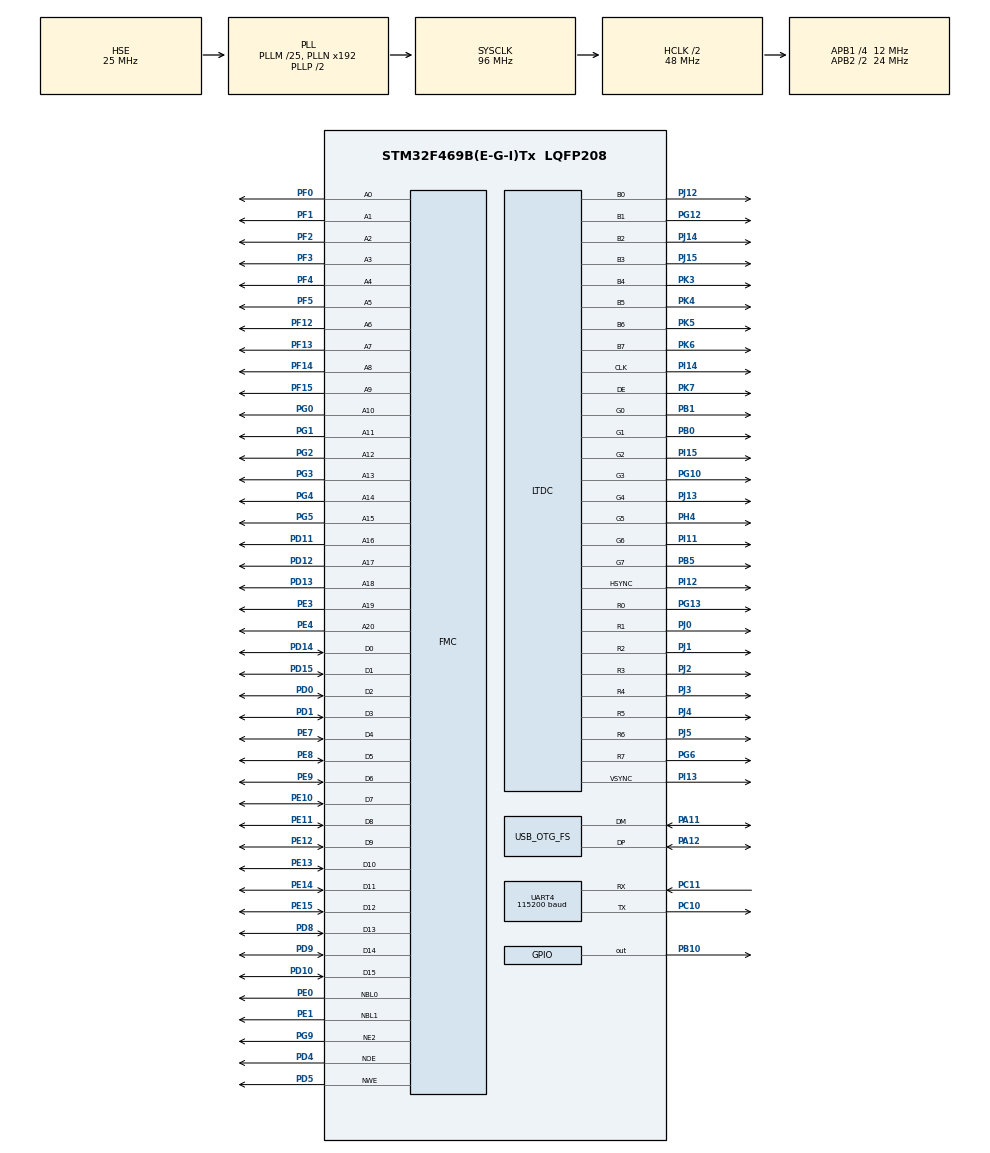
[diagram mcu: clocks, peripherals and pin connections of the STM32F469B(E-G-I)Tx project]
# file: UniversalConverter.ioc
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FMC.AddressSetupTime1=10
FMC.BusTurnAroundDuration1=2
FMC.DataSetupTime1=10
FMC.WriteFifo1=FMC_WRITE_FIFO_DISABLE
FMC.WriteFifo2=FMC_WRITE_FIFO_DISABLE
FMC.WriteFifo3=FMC_WRITE_FIFO_DISABLE
FMC.WriteFifo4=FMC_WRITE_FIFO_DISABLE
LTDC.ActiveW=800
LTDC.Blue=50
LTDC.Green=120
LTDC.HBP=40
LTDC.HFP=40
LTDC.HSync=48
LTDC.Red=255
LTDC.VBP=31
LTDC.VFP=13
LTDC.VSync=1
Mcu.Family=STM32F4
Mcu.Name=STM32F469B(E-G-I)Tx
Mcu.Package=LQFP208
NVIC.LTDC_IRQn=true\:0\:0\:false\:false\:true\:true\:true
NVIC.OTG_FS_IRQn=true\:0\:0\:false\:false\:true\:false\:true
NVIC.PriorityGroup=NVIC_PRIORITYGROUP_4
NVIC.UART4_IRQn=true\:0\:0\:false\:false\:true\:true\:true
PA11.Mode=Device_Only
PA11.Signal=USB_OTG_FS_DM
PA12.Mode=Device_Only
PA12.Signal=USB_OTG_FS_DP
PB0.GPIO_Mode=GPIO_MODE_AF_PP
PB0.GPIO_PuPd=GPIO_NOPULL
PB0.GPIO_Speed=GPIO_SPEED_FREQ_VERY_HIGH
PB0.Mode=RGB888
PB0.Signal=LTDC_G1
PB1.GPIO_Mode=GPIO_MODE_AF_PP
PB1.GPIO_PuPd=GPIO_NOPULL
PB1.GPIO_Speed=GPIO_SPEED_FREQ_VERY_HIGH
PB1.Mode=RGB888
PB1.Signal=LTDC_G0
PB10.GPIO_PuPd=GPIO_PULLUP
PB10.PinState=GPIO_PIN_SET
PB10.Signal=GPIO_Output
PB5.GPIO_Mode=GPIO_MODE_AF_PP
PB5.GPIO_PuPd=GPIO_NOPULL
PB5.GPIO_Speed=GPIO_SPEED_FREQ_VERY_HIGH
PB5.Mode=RGB888
PB5.Signal=LTDC_G7
PC10.Mode=Asynchronous
PC10.Signal=UART4_TX
PC11.Mode=Asynchronous
PC11.Signal=UART4_RX
PC14/OSC32_IN.Mode=LSE-External-Oscillator
PC14/OSC32_IN.Signal=RCC_OSC32_IN
PC15/OSC32_OUT.Mode=LSE-External-Oscillator
PC15/OSC32_OUT.Signal=RCC_OSC32_OUT
PD0.GPIO_Mode=GPIO_MODE_AF_PP
PD0.GPIO_PuPd=GPIO_PULLUP
PD0.Signal=FMC_D2_DA2
PD1.GPIO_PuPd=GPIO_PULLUP
PD1.Signal=FMC_D3_DA3
PD10.GPIO_PuPd=GPIO_PULLUP
PD10.Signal=FMC_D15_DA15
PD11.GPIO_PuPd=GPIO_PULLUP
PD11.Signal=FMC_A16_CLE
PD12.GPIO_PuPd=GPIO_PULLUP
PD12.Signal=FMC_A17_ALE
PD13.GPIO_PuPd=GPIO_PULLUP
PD13.Signal=FMC_A18
PD14.GPIO_PuPd=GPIO_PULLUP
PD14.Signal=FMC_D0_DA0
PD15.GPIO_PuPd=GPIO_PULLUP
PD15.Signal=FMC_D1_DA1
PD4.GPIO_PuPd=GPIO_PULLUP
PD4.Signal=FMC_NOE
PD5.GPIO_PuPd=GPIO_PULLUP
PD5.Signal=FMC_NWE
PD8.GPIO_PuPd=GPIO_PULLUP
PD8.Signal=FMC_D13_DA13
PD9.GPIO_PuPd=GPIO_PULLUP
PD9.Signal=FMC_D14_DA14
PE0.GPIO_PuPd=GPIO_PULLUP
PE0.Signal=FMC_NBL0
PE1.GPIO_PuPd=GPIO_PULLUP
PE1.Signal=FMC_NBL1
PE10.GPIO_PuPd=GPIO_PULLUP
PE10.Signal=FMC_D7_DA7
PE11.GPIO_PuPd=GPIO_PULLUP
PE11.Signal=FMC_D8_DA8
PE12.GPIO_PuPd=GPIO_PULLUP
PE12.Signal=FMC_D9_DA9
PE13.GPIO_PuPd=GPIO_PULLUP
PE13.Signal=FMC_D10_DA10
PE14.GPIO_PuPd=GPIO_PULLUP
PE14.Signal=FMC_D11_DA11
PE15.GPIO_PuPd=GPIO_PULLUP
PE15.Signal=FMC_D12_DA12
PE3.GPIO_PuPd=GPIO_PULLUP
PE3.Signal=FMC_A19
PE4.GPIO_PuPd=GPIO_PULLUP
PE4.Signal=FMC_A20
PE7.GPIO_PuPd=GPIO_PULLUP
PE7.Signal=FMC_D4_DA4
PE8.GPIO_PuPd=GPIO_PULLUP
PE8.Signal=FMC_D5_DA5
PE9.GPIO_PuPd=GPIO_PULLUP
PE9.Signal=FMC_D6_DA6
PF0.GPIO_PuPd=GPIO_PULLUP
PF0.Signal=FMC_A0
PF1.GPIO_PuPd=GPIO_PULLUP
PF1.Signal=FMC_A1
PF12.GPIO_PuPd=GPIO_PULLUP
PF12.Signal=FMC_A6
PF13.GPIO_PuPd=GPIO_PULLUP
PF13.Signal=FMC_A7
PF14.GPIO_PuPd=GPIO_PULLUP
PF14.Signal=FMC_A8
PF15.GPIO_PuPd=GPIO_PULLUP
PF15.Signal=FMC_A9
PF2.GPIO_PuPd=GPIO_PULLUP
PF2.Signal=FMC_A2
PF3.GPIO_PuPd=GPIO_PULLUP
PF3.Signal=FMC_A3
PF4.GPIO_PuPd=GPIO_PULLUP
PF4.Signal=FMC_A4
PF5.GPIO_PuPd=GPIO_PULLUP
PF5.Signal=FMC_A5
PG0.GPIO_PuPd=GPIO_PULLUP
PG0.Signal=FMC_A10
PG1.GPIO_PuPd=GPIO_PULLUP
PG1.Signal=FMC_A11
PG10.GPIO_Mode=GPIO_MODE_AF_PP
PG10.GPIO_PuPd=GPIO_NOPULL
PG10.GPIO_Speed=GPIO_SPEED_FREQ_VERY_HIGH
PG10.Mode=RGB888
PG10.Signal=LTDC_G3
PG12.GPIO_Mode=GPIO_MODE_AF_PP
PG12.GPIO_PuPd=GPIO_NOPULL
PG12.GPIO_Speed=GPIO_SPEED_FREQ_VERY_HIGH
PG12.Mode=RGB888
PG12.Signal=LTDC_B1
PG13.GPIO_Mode=GPIO_MODE_AF_PP
PG13.GPIO_PuPd=GPIO_NOPULL
PG13.GPIO_Speed=GPIO_SPEED_FREQ_VERY_HIGH
PG13.Mode=RGB888
PG13.Signal=LTDC_R0
PG2.GPIO_PuPd=GPIO_PULLUP
PG2.Signal=FMC_A12
PG3.GPIO_PuPd=GPIO_PULLUP
PG3.Signal=FMC_A13
PG4.GPIO_PuPd=GPIO_PULLUP
PG4.Signal=FMC_A14_BA0
PG5.GPIO_PuPd=GPIO_PULLUP
PG5.Signal=FMC_A15_BA1
PG6.GPIO_Mode=GPIO_MODE_AF_PP
PG6.GPIO_PuPd=GPIO_NOPULL
PG6.GPIO_Speed=GPIO_SPEED_FREQ_VERY_HIGH
PG6.Mode=RGB888
PG6.Signal=LTDC_R7
PG9.GPIO_PuPd=GPIO_PULLUP
PG9.Mode=NorPsramChipSelect2_1
PG9.Signal=FMC_NE2
PH0/OSC_IN.Mode=HSE-External-Oscillator
PH0/OSC_IN.Signal=RCC_OSC_IN
PH1/OSC_OUT.Mode=HSE-External-Oscillator
PH1/OSC_OUT.Signal=RCC_OSC_OUT
PH4.GPIO_Mode=GPIO_MODE_AF_PP
PH4.GPIO_PuPd=GPIO_NOPULL
PH4.GPIO_Speed=GPIO_SPEED_FREQ_VERY_HIGH
PH4.Mode=RGB888
PH4.Signal=LTDC_G5
PI11.GPIO_Mode=GPIO_MODE_AF_PP
PI11.GPIO_PuPd=GPIO_NOPULL
PI11.GPIO_Speed=GPIO_SPEED_FREQ_VERY_HIGH
PI11.Mode=RGB888
PI11.Signal=LTDC_G6
PI12.GPIO_Mode=GPIO_MODE_AF_PP
PI12.GPIO_PuPd=GPIO_NOPULL
PI12.GPIO_Speed=GPIO_SPEED_FREQ_VERY_HIGH
PI12.Mode=RGB888
PI12.Signal=LTDC_HSYNC
PI13.GPIO_Mode=GPIO_MODE_AF_PP
PI13.GPIO_PuPd=GPIO_NOPULL
PI13.GPIO_Speed=GPIO_SPEED_FREQ_VERY_HIGH
PI13.Mode=RGB888
PI13.Signal=LTDC_VSYNC
PI14.GPIO_Mode=GPIO_MODE_AF_PP
PI14.GPIO_PuPd=GPIO_NOPULL
PI14.GPIO_Speed=GPIO_SPEED_FREQ_VERY_HIGH
PI14.Mode=RGB888
PI14.Signal=LTDC_CLK
PI15.GPIO_Mode=GPIO_MODE_AF_PP
PI15.GPIO_PuPd=GPIO_NOPULL
PI15.GPIO_Speed=GPIO_SPEED_FREQ_VERY_HIGH
PI15.Mode=RGB888
PI15.Signal=LTDC_G2
PJ0.GPIO_Mode=GPIO_MODE_AF_PP
PJ0.GPIO_PuPd=GPIO_NOPULL
PJ0.GPIO_Speed=GPIO_SPEED_FREQ_VERY_HIGH
PJ0.Mode=RGB888
PJ0.Signal=LTDC_R1
PJ1.GPIO_Mode=GPIO_MODE_AF_PP
PJ1.GPIO_PuPd=GPIO_NOPULL
PJ1.GPIO_Speed=GPIO_SPEED_FREQ_VERY_HIGH
PJ1.Mode=RGB888
PJ1.Signal=LTDC_R2
PJ12.GPIO_Mode=GPIO_MODE_AF_PP
PJ12.GPIO_PuPd=GPIO_NOPULL
PJ12.GPIO_Speed=GPIO_SPEED_FREQ_VERY_HIGH
PJ12.Mode=RGB888
PJ12.Signal=LTDC_B0
PJ13.GPIO_Mode=GPIO_MODE_AF_PP
PJ13.GPIO_PuPd=GPIO_NOPULL
PJ13.GPIO_Speed=GPIO_SPEED_FREQ_VERY_HIGH
PJ13.Mode=RGB888
PJ13.Signal=LTDC_G4
PJ14.GPIO_Mode=GPIO_MODE_AF_PP
PJ14.GPIO_PuPd=GPIO_NOPULL
PJ14.GPIO_Speed=GPIO_SPEED_FREQ_VERY_HIGH
PJ14.Mode=RGB888
PJ14.Signal=LTDC_B2
PJ15.GPIO_Mode=GPIO_MODE_AF_PP
PJ15.GPIO_PuPd=GPIO_NOPULL
PJ15.GPIO_Speed=GPIO_SPEED_FREQ_VERY_HIGH
PJ15.Mode=RGB888
PJ15.Signal=LTDC_B3
PJ2.GPIO_Mode=GPIO_MODE_AF_PP
PJ2.GPIO_PuPd=GPIO_NOPULL
PJ2.GPIO_Speed=GPIO_SPEED_FREQ_VERY_HIGH
PJ2.Mode=RGB888
PJ2.Signal=LTDC_R3
PJ3.GPIO_Mode=GPIO_MODE_AF_PP
PJ3.GPIO_PuPd=GPIO_NOPULL
PJ3.GPIO_Speed=GPIO_SPEED_FREQ_VERY_HIGH
PJ3.Mode=RGB888
PJ3.Signal=LTDC_R4
PJ4.GPIO_Mode=GPIO_MODE_AF_PP
PJ4.GPIO_PuPd=GPIO_NOPULL
PJ4.GPIO_Speed=GPIO_SPEED_FREQ_VERY_HIGH
PJ4.Mode=RGB888
PJ4.Signal=LTDC_R5
PJ5.GPIO_Mode=GPIO_MODE_AF_PP
PJ5.GPIO_PuPd=GPIO_NOPULL
PJ5.GPIO_Speed=GPIO_SPEED_FREQ_VERY_HIGH
PJ5.Mode=RGB888
PJ5.Signal=LTDC_R6
PK3.GPIO_Mode=GPIO_MODE_AF_PP
PK3.GPIO_PuPd=GPIO_NOPULL
PK3.GPIO_Speed=GPIO_SPEED_FREQ_VERY_HIGH
PK3.Mode=RGB888
PK3.Signal=LTDC_B4
PK4.GPIO_Mode=GPIO_MODE_AF_PP
PK4.GPIO_PuPd=GPIO_NOPULL
PK4.GPIO_Speed=GPIO_SPEED_FREQ_VERY_HIGH
PK4.Mode=RGB888
PK4.Signal=LTDC_B5
PK5.GPIO_Mode=GPIO_MODE_AF_PP
PK5.GPIO_PuPd=GPIO_NOPULL
PK5.GPIO_Speed=GPIO_SPEED_FREQ_VERY_HIGH
PK5.Mode=RGB888
PK5.Signal=LTDC_B6
PK6.GPIO_Mode=GPIO_MODE_AF_PP
PK6.GPIO_PuPd=GPIO_NOPULL
PK6.GPIO_Speed=GPIO_SPEED_FREQ_VERY_HIGH
PK6.Mode=RGB888
PK6.Signal=LTDC_B7
PK7.GPIO_Mode=GPIO_MODE_AF_PP
PK7.GPIO_PuPd=GPIO_NOPULL
PK7.GPIO_Speed=GPIO_SPEED_FREQ_VERY_HIGH
PK7.Mode=RGB888
PK7.Signal=LTDC_DE
ProjectManager.HeapSize=0x200
ProjectManager.StackSize=0x400
ProjectManager.TargetToolchain=STM32CubeIDE
RCC.AHBCLKDivider=RCC_SYSCLK_DIV2
RCC.AHBFreq_Value=48000000
RCC.APB1CLKDivider=RCC_HCLK_DIV4
RCC.APB1Freq_Value=12000000
RCC.APB1TimFreq_Value=24000000
RCC.APB2CLKDivider=RCC_HCLK_DIV2
RCC.APB2Freq_Value=24000000
RCC.APB2TimFreq_Value=48000000
RCC.CortexFreq_Value=48000000
RCC.HCLKFreq_Value=48000000
RCC.PLLM=25
RCC.PLLSAIP=RCC_PLLSAIP_DIV4
RCC.SYSCLKFreq_VALUE=96000000
RCC.SYSCLKSource=RCC_SYSCLKSOURCE_PLLCLK
RCC.USBFreq_Value=48000000
RCC.VCOOutputFreq_Value=192000000
SH.FMC_A0.0=FMC_A0,21b-a1
SH.FMC_A1.0=FMC_A1,21b-a1
SH.FMC_A10.0=FMC_A10,21b-a1
SH.FMC_A11.0=FMC_A11,21b-a1
SH.FMC_A12.0=FMC_A12,21b-a1
SH.FMC_A13.0=FMC_A13,21b-a1
SH.FMC_A14_BA0.0=FMC_A14,21b-a1
SH.FMC_A15_BA1.0=FMC_A15,21b-a1
SH.FMC_A16_CLE.0=FMC_A16,21b-a1
SH.FMC_A17_ALE.0=FMC_A17,21b-a1
SH.FMC_A18.0=FMC_A18,21b-a1
SH.FMC_A19.0=FMC_A19,21b-a1
SH.FMC_A2.0=FMC_A2,21b-a1
SH.FMC_A20.0=FMC_A20,21b-a1
SH.FMC_A3.0=FMC_A3,21b-a1
SH.FMC_A4.0=FMC_A4,21b-a1
SH.FMC_A5.0=FMC_A5,21b-a1
SH.FMC_A6.0=FMC_A6,21b-a1
SH.FMC_A7.0=FMC_A7,21b-a1
SH.FMC_A8.0=FMC_A8,21b-a1
SH.FMC_A9.0=FMC_A9,21b-a1
SH.FMC_D0_DA0.0=FMC_D0,16b-d1
SH.FMC_D10_DA10.0=FMC_D10,16b-d1
SH.FMC_D11_DA11.0=FMC_D11,16b-d1
SH.FMC_D12_DA12.0=FMC_D12,16b-d1
SH.FMC_D13_DA13.0=FMC_D13,16b-d1
SH.FMC_D14_DA14.0=FMC_D14,16b-d1
SH.FMC_D15_DA15.0=FMC_D15,16b-d1
SH.FMC_D1_DA1.0=FMC_D1,16b-d1
SH.FMC_D2_DA2.0=FMC_D2,16b-d1
SH.FMC_D3_DA3.0=FMC_D3,16b-d1
SH.FMC_D4_DA4.0=FMC_D4,16b-d1
SH.FMC_D5_DA5.0=FMC_D5,16b-d1
SH.FMC_D6_DA6.0=FMC_D6,16b-d1
SH.FMC_D7_DA7.0=FMC_D7,16b-d1
SH.FMC_D8_DA8.0=FMC_D8,16b-d1
SH.FMC_D9_DA9.0=FMC_D9,16b-d1
SH.FMC_NBL0.0=FMC_NBL0,2ByteEnable1
SH.FMC_NBL1.0=FMC_NBL1,2ByteEnable1
SH.FMC_NOE.0=FMC_NOE,Sram1
SH.FMC_NWE.0=FMC_NWE,Sram1
UART4.BaudRate=115200
UART4.VirtualMode=Asynchronous
USB_DEVICE.CLASS_NAME_FS=CDC
USB_DEVICE.VirtualMode-CDC_FS=Cdc
USB_DEVICE.VirtualModeFS=Cdc_FS
USB_OTG_FS.VirtualMode=Device_Only
USB_OTG_FS.lpm_enable=DISABLE
VP_USB_DEVICE_VS_USB_DEVICE_CDC_FS.Mode=CDC_FS
board=custom

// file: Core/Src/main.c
/* USER CODE BEGIN Header */
/**
  ******************************************************************************
  * @file           : main.c
  * @brief          : Main program body
  ******************************************************************************
  * @attention
  *
  * <h2><center>&copy; Copyright (c) 2021 STMicroelectronics.
  * All rights reserved.</center></h2>
  *
  * This software component is licensed by ST under Ultimate Liberty license
  * SLA0044, the "License"; You may not use this file except in compliance with
  * the License. You may obtain a copy of the License at:
  *                             www.st.com/SLA0044
  *
  ******************************************************************************
  */
/* USER CODE END Header */
#include "main.h"
#include "usb_device.h"
#include "stdbool.h"

LTDC_HandleTypeDef hltdc;

UART_HandleTypeDef huart4;

SRAM_HandleTypeDef hsram1;

/* USER CODE BEGIN PV */
uint8_t rx_buff[1];
uint8_t cmd_arr[10];
uint8_t curr_idx = 0;
bool debug_en = false;
/* USER CODE END PV */

void SystemClock_Config(void);
static void MX_GPIO_Init(void);
static void MX_FMC_Init(void);
static void MX_LTDC_Init(void);
static void MX_UART4_Init(void);
/* USER CODE BEGIN PFP */
void HAL_UART_RxCpltCallback(UART_HandleTypeDef *huart);
void buildCmd();
void printDBM();
void debugMenu();
/* USER CODE END PFP */

int main(void)
{

  /* MCU Configuration--------------------------------------------------------*/

  /* Reset of all peripherals, Initializes the Flash interface and the Systick. */
  HAL_Init();

  /* Configure the system clock */
  SystemClock_Config();

  /* Initialize all configured peripherals */
  MX_GPIO_Init();
  MX_FMC_Init();
  MX_USB_DEVICE_Init();
  MX_LTDC_Init();
  MX_UART4_Init();
  /* USER CODE BEGIN 2 */
  HAL_UART_Receive_IT(&huart4, rx_buff, sizeof(rx_buff));
  /* USER CODE END 2 */

  /* Infinite loop */
  while (1)
  {

  }
}

void SystemClock_Config(void)
{
  RCC_OscInitTypeDef RCC_OscInitStruct = {0};
  RCC_ClkInitTypeDef RCC_ClkInitStruct = {0};

  /** Configure the main internal regulator output voltage
  */
  __HAL_RCC_PWR_CLK_ENABLE();
  __HAL_PWR_VOLTAGESCALING_CONFIG(PWR_REGULATOR_VOLTAGE_SCALE3);
  /** Initializes the RCC Oscillators according to the specified parameters
  * in the RCC_OscInitTypeDef structure.
  */
  RCC_OscInitStruct.OscillatorType = RCC_OSCILLATORTYPE_HSE;
  RCC_OscInitStruct.HSEState = RCC_HSE_ON;
  RCC_OscInitStruct.PLL.PLLState = RCC_PLL_ON;
  RCC_OscInitStruct.PLL.PLLSource = RCC_PLLSOURCE_HSE;
  RCC_OscInitStruct.PLL.PLLM = 25;
  RCC_OscInitStruct.PLL.PLLN = 192;
  RCC_OscInitStruct.PLL.PLLP = RCC_PLLP_DIV2;
  RCC_OscInitStruct.PLL.PLLQ = 4;
  RCC_OscInitStruct.PLL.PLLR = 2;
  if (HAL_RCC_OscConfig(&RCC_OscInitStruct) != HAL_OK)
  {
    Error_Handler();
  }
  /** Initializes the CPU, AHB and APB buses clocks
  */
  RCC_ClkInitStruct.ClockType = RCC_CLOCKTYPE_HCLK|RCC_CLOCKTYPE_SYSCLK
                              |RCC_CLOCKTYPE_PCLK1|RCC_CLOCKTYPE_PCLK2;
  RCC_ClkInitStruct.SYSCLKSource = RCC_SYSCLKSOURCE_PLLCLK;
  RCC_ClkInitStruct.AHBCLKDivider = RCC_SYSCLK_DIV2;
  RCC_ClkInitStruct.APB1CLKDivider = RCC_HCLK_DIV4;
  RCC_ClkInitStruct.APB2CLKDivider = RCC_HCLK_DIV2;

  if (HAL_RCC_ClockConfig(&RCC_ClkInitStruct, FLASH_LATENCY_1) != HAL_OK)
  {
    Error_Handler();
  }
}

static void MX_LTDC_Init(void)
{

  LTDC_LayerCfgTypeDef pLayerCfg = {0};
  LTDC_LayerCfgTypeDef pLayerCfg1 = {0};

  hltdc.Instance = LTDC;
  hltdc.Init.HSPolarity = LTDC_HSPOLARITY_AL;
  hltdc.Init.VSPolarity = LTDC_VSPOLARITY_AL;
  hltdc.Init.DEPolarity = LTDC_DEPOLARITY_AL;
  hltdc.Init.PCPolarity = LTDC_PCPOLARITY_IPC;
  hltdc.Init.HorizontalSync = 47;
  hltdc.Init.VerticalSync = 0;
  hltdc.Init.AccumulatedHBP = 87;
  hltdc.Init.AccumulatedVBP = 31;
  hltdc.Init.AccumulatedActiveW = 887;
  hltdc.Init.AccumulatedActiveH = 511;
  hltdc.Init.TotalWidth = 927;
  hltdc.Init.TotalHeigh = 524;
  hltdc.Init.Backcolor.Blue = 50;
  hltdc.Init.Backcolor.Green = 120;
  hltdc.Init.Backcolor.Red = 255;
  if (HAL_LTDC_Init(&hltdc) != HAL_OK)
  {
    Error_Handler();
  }
  pLayerCfg.WindowX0 = 0;
  pLayerCfg.WindowX1 = 0;
  pLayerCfg.WindowY0 = 0;
  pLayerCfg.WindowY1 = 0;
  pLayerCfg.PixelFormat = LTDC_PIXEL_FORMAT_ARGB8888;
  pLayerCfg.Alpha = 0;
  pLayerCfg.Alpha0 = 0;
  pLayerCfg.BlendingFactor1 = LTDC_BLENDING_FACTOR1_CA;
  pLayerCfg.BlendingFactor2 = LTDC_BLENDING_FACTOR2_CA;
  pLayerCfg.FBStartAdress = 0;
  pLayerCfg.ImageWidth = 0;
  pLayerCfg.ImageHeight = 0;
  pLayerCfg.Backcolor.Blue = 0;
  pLayerCfg.Backcolor.Green = 0;
  pLayerCfg.Backcolor.Red = 0;
  if (HAL_LTDC_ConfigLayer(&hltdc, &pLayerCfg, 0) != HAL_OK)
  {
    Error_Handler();
  }
  pLayerCfg1.WindowX0 = 0;
  pLayerCfg1.WindowX1 = 0;
  pLayerCfg1.WindowY0 = 0;
  pLayerCfg1.WindowY1 = 0;
  pLayerCfg1.PixelFormat = LTDC_PIXEL_FORMAT_ARGB8888;
  pLayerCfg1.Alpha = 0;
  pLayerCfg1.Alpha0 = 0;
  pLayerCfg1.BlendingFactor1 = LTDC_BLENDING_FACTOR1_CA;
  pLayerCfg1.BlendingFactor2 = LTDC_BLENDING_FACTOR2_CA;
  pLayerCfg1.FBStartAdress = 0;
  pLayerCfg1.ImageWidth = 0;
  pLayerCfg1.ImageHeight = 0;
  pLayerCfg1.Backcolor.Blue = 0;
  pLayerCfg1.Backcolor.Green = 0;
  pLayerCfg1.Backcolor.Red = 0;
  if (HAL_LTDC_ConfigLayer(&hltdc, &pLayerCfg1, 1) != HAL_OK)
  {
    Error_Handler();
  }

}

static void MX_UART4_Init(void)
{

  huart4.Instance = UART4;
  huart4.Init.BaudRate = 115200;
  huart4.Init.WordLength = UART_WORDLENGTH_8B;
  huart4.Init.StopBits = UART_STOPBITS_1;
  huart4.Init.Parity = UART_PARITY_NONE;
  huart4.Init.Mode = UART_MODE_TX_RX;
  huart4.Init.HwFlowCtl = UART_HWCONTROL_NONE;
  huart4.Init.OverSampling = UART_OVERSAMPLING_16;
  if (HAL_UART_Init(&huart4) != HAL_OK)
  {
    Error_Handler();
  }

}

/* FMC initialization function */
static void MX_FMC_Init(void)
{

  FMC_NORSRAM_TimingTypeDef Timing = {0};

  /** Perform the SRAM1 memory initialization sequence
  */
  hsram1.Instance = FMC_NORSRAM_DEVICE;
  hsram1.Extended = FMC_NORSRAM_EXTENDED_DEVICE;
  /* hsram1.Init */
  hsram1.Init.NSBank = FMC_NORSRAM_BANK2;
  hsram1.Init.DataAddressMux = FMC_DATA_ADDRESS_MUX_DISABLE;
  hsram1.Init.MemoryType = FMC_MEMORY_TYPE_SRAM;
  hsram1.Init.MemoryDataWidth = FMC_NORSRAM_MEM_BUS_WIDTH_16;
  hsram1.Init.BurstAccessMode = FMC_BURST_ACCESS_MODE_DISABLE;
  hsram1.Init.WaitSignalPolarity = FMC_WAIT_SIGNAL_POLARITY_LOW;
  hsram1.Init.WaitSignalActive = FMC_WAIT_TIMING_BEFORE_WS;
  hsram1.Init.WriteOperation = FMC_WRITE_OPERATION_DISABLE;
  hsram1.Init.WaitSignal = FMC_WAIT_SIGNAL_DISABLE;
  hsram1.Init.ExtendedMode = FMC_EXTENDED_MODE_DISABLE;
  hsram1.Init.AsynchronousWait = FMC_ASYNCHRONOUS_WAIT_DISABLE;
  hsram1.Init.WriteBurst = FMC_WRITE_BURST_DISABLE;
  hsram1.Init.ContinuousClock = FMC_CONTINUOUS_CLOCK_SYNC_ONLY;
  hsram1.Init.WriteFifo = FMC_WRITE_FIFO_DISABLE;
  hsram1.Init.PageSize = FMC_PAGE_SIZE_NONE;
  /* Timing */
  Timing.AddressSetupTime = 10;
  Timing.AddressHoldTime = 15;
  Timing.DataSetupTime = 10;
  Timing.BusTurnAroundDuration = 2;
  Timing.CLKDivision = 16;
  Timing.DataLatency = 17;
  Timing.AccessMode = FMC_ACCESS_MODE_A;
  /* ExtTiming */

  if (HAL_SRAM_Init(&hsram1, &Timing, NULL) != HAL_OK)
  {
    Error_Handler( );
  }

}

static void MX_GPIO_Init(void)
{
  GPIO_InitTypeDef GPIO_InitStruct = {0};

  /* GPIO Ports Clock Enable */
  __HAL_RCC_GPIOE_CLK_ENABLE();
  __HAL_RCC_GPIOC_CLK_ENABLE();
  __HAL_RCC_GPIOI_CLK_ENABLE();
  __HAL_RCC_GPIOF_CLK_ENABLE();
  __HAL_RCC_GPIOH_CLK_ENABLE();
  __HAL_RCC_GPIOB_CLK_ENABLE();
  __HAL_RCC_GPIOJ_CLK_ENABLE();
  __HAL_RCC_GPIOG_CLK_ENABLE();
  __HAL_RCC_GPIOD_CLK_ENABLE();
  __HAL_RCC_GPIOA_CLK_ENABLE();
  __HAL_RCC_GPIOK_CLK_ENABLE();

  /*Configure GPIO pin Output Level */
  HAL_GPIO_WritePin(GPIOB, GPIO_PIN_10, GPIO_PIN_SET);

  /*Configure GPIO pin : PB10 */
  GPIO_InitStruct.Pin = GPIO_PIN_10;
  GPIO_InitStruct.Mode = GPIO_MODE_OUTPUT_PP;
  GPIO_InitStruct.Pull = GPIO_PULLUP;
  GPIO_InitStruct.Speed = GPIO_SPEED_FREQ_LOW;
  HAL_GPIO_Init(GPIOB, &GPIO_InitStruct);

}

/* USER CODE BEGIN 4 */
void HAL_UART_RxCpltCallback(UART_HandleTypeDef *huart)
{
	HAL_UART_Transmit(&huart4, rx_buff, sizeof(rx_buff), 100);

	if (*rx_buff == '\n')
	{
		debugMenu();
	}
	else
	{
		buildCmd();
	}

    HAL_UART_Receive_IT(&huart4, rx_buff, sizeof(rx_buff));
}

void buildCmd()
{
	if(curr_idx < sizeof(cmd_arr))
	{
		cmd_arr[curr_idx] = *rx_buff;
	}
	curr_idx++;
	debug_en = true;
}

void printDBM()
// Contains the structure of the Debug Menu that is printed out to the user
{
	uint8_t tx_buff[] = {"\n? - Help"
						 "\nH - Hello World\n\n"};
	HAL_UART_Transmit(&huart4, tx_buff, sizeof(tx_buff), 100);
}

void debugMenu()
// Logic for traversing the various commands in the menu
{
	if (debug_en)
	{
		int rb_idx = 0;
		uint8_t tx_buff[] = {"Hello World\n"};

		switch(cmd_arr[rb_idx])
		{
		case '?':
			if (rb_idx == curr_idx - 1)
			{
				printDBM();
			}
			break;
		case 'H':
			if (rb_idx == curr_idx - 1)
			{
				HAL_UART_Transmit(&huart4, tx_buff, sizeof(tx_buff), 100);
			}
			break;
		}
	}
	curr_idx = 0;
	debug_en = false;
}
/* USER CODE END 4 */

void Error_Handler(void)
{
  __disable_irq();
  while (1)
  {
  }
}

/************************ (C) COPYRIGHT STMicroelectronics *****END OF FILE****/
